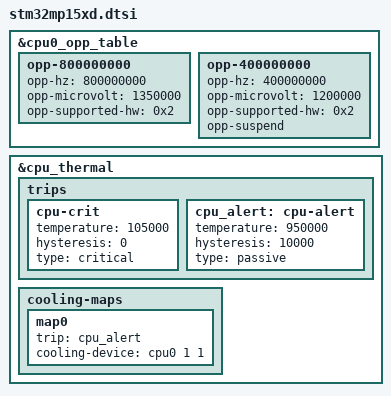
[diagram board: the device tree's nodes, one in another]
// SPDX-License-Identifier: (GPL-2.0+ OR BSD-3-Clause)
/*
 * Copyright (C) STMicroelectronics 2019 - All Rights Reserved
 * Author: Alexandre Torgue <alexandre.torgue@st.com> for STMicroelectronics.
 */

&cpu0_opp_table {
		opp-800000000 {
			opp-hz = /bits/ 64 <800000000>;
			opp-microvolt = <1350000>;
			opp-supported-hw = <0x2>;
		};
		opp-400000000 {
			opp-hz = /bits/ 64 <400000000>;
			opp-microvolt = <1200000>;
			opp-supported-hw = <0x2>;
			opp-suspend;
		};
};

&cpu_thermal {
	trips {
		cpu-crit {
			temperature = <105000>;
			hysteresis = <0>;
			type = "critical";
		};

		cpu_alert: cpu-alert {
			temperature = <950000>;
			hysteresis = <10000>;
			type = "passive";
		};
	};

	cooling-maps {
		map0 {
			trip = <&cpu_alert>;
			cooling-device = <&cpu0 1 1>;
		};
	};
};
